# CY8C5888LTI_LP097 register map
File version: 0.1
Registers are 8-bit, read-write, no defined reset value unless marked. A register's access mark holds for its fields unless they carry their own. Offsets are from the block's base; [hi:lo] are bit positions; {n}, {i} and the like mark numbered series; 'fields as' and 'values as' point back to an identical list.

## Timer_1
Base 0x00000000
0x40006506 Timer_1_COUNTER 16-bit — UDB.A0 - Current Down Counter Value
0x40006526 Timer_1_PERIOD 16-bit — UDB.D0 - Assigned Period
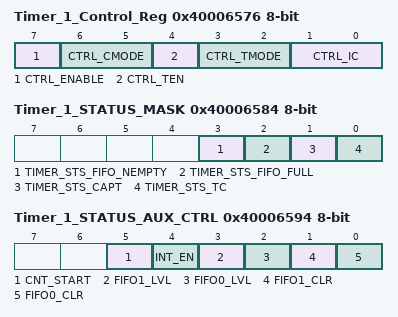
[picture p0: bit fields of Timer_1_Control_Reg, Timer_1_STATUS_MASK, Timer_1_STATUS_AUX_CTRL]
0x40006576 Timer_1_Control_Reg — UDB Control Register - Assigned Control Register Value
  [7] CTRL_ENABLE — Enable the Timer
  [6:5] CTRL_CMODE — Capture Mode
  [4] CTRL_TEN — Trigger Enable Bit
  [3:2] CTRL_TMODE — Trigger Mode
  [1:0] CTRL_IC — Interrupt Count
0x40006584 Timer_1_STATUS_MASK — UDB Status bits Interrupt Mask Enable Register
  [3] TIMER_STS_FIFO_NEMPTY ro — FIFO Empty status
  [2] TIMER_STS_FIFO_FULL ro — FIFO Full Status
  [1] TIMER_STS_CAPT ro — Enables the Interrupt on Capture
  [0] TIMER_STS_TC ro — Enables the Interrupt on TC
0x40006594 Timer_1_STATUS_AUX_CTRL — UDB Auxilliary Control Register
  [5] CNT_START — FIFO0 clear
    0=E_CNT_START0 (Disable counter); 1=E_CNT_START1 (Enable counter)
  [4] INT_EN
    0=E_INT_EN0 (Interrupt disabled); 1=E_INT_EN1 (Interrupt enabled)
  [3] FIFO1_LVL — FIFO level
    0=E_FIFO_LVL_0 (FIFO LVL: input mode: FIFO not full; output mode: FIFO not empty); 1=E_FIFO_LVL_1 (FIFO LVL: input mode: FIFO at least 1/2 empty; output mode: FIFO at least 1/2 full)
  [2] FIFO0_LVL — FIFO level
    values as FIFO1_LVL
  [1] FIFO1_CLR — FIFO1 clear
    0=E_FIFO_CLR_0 (Normal FIFO operation); 1=E_FIFO_CLR_1 (Clear FIFO state)
  [0] FIFO0_CLR — FIFO0 clear
    values as FIFO1_CLR

## PWM_5
Base 0x00000000
0x40006524 PWM_5_COMPARE_Reg 16-bit — UDB.D0 - Assigned Compare Value
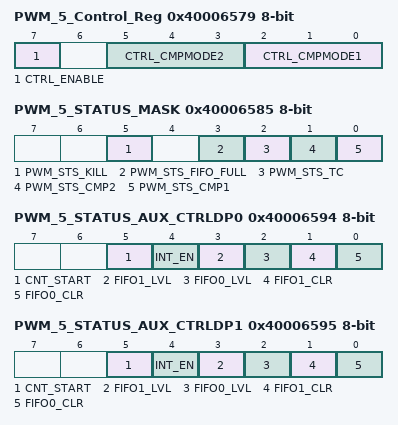
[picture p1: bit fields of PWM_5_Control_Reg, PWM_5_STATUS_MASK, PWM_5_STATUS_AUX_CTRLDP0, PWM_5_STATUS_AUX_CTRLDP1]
0x40006579 PWM_5_Control_Reg — UDB Control Register - Assigned Control Register Value
  [7] CTRL_ENABLE — Enable the PWM
  [5:3] CTRL_CMPMODE2 — Compare mode 2
  [2:0] CTRL_CMPMODE1 — Compare mode 1
0x40006585 PWM_5_STATUS_MASK — UDB Status bits Interrupt Mask Enable Register
  [5] PWM_STS_KILL ro — Enables the Interrupt on Kill
  [3] PWM_STS_FIFO_FULL ro — FIFO Full Status Mask
  [2] PWM_STS_TC ro — Enables the Interrupt on Terminal Count
  [1] PWM_STS_CMP2 ro — Enables the Interrupt on Compare 2
  [0] PWM_STS_CMP1 ro — Enables the Interrupt on Compare 1
0x40006594 PWM_5_STATUS_AUX_CTRLDP0 — UDB Auxilliary Control Register
  [5] CNT_START — FIFO0 clear
    0=E_CNT_START0 (Disable counter); 1=E_CNT_START1 (Enable counter)
  [4] INT_EN
    0=E_INT_EN0 (Interrupt disabled); 1=E_INT_EN1 (Interrupt enabled)
  [3] FIFO1_LVL — FIFO level
    0=E_FIFO_LVL_0 (FIFO LVL: input mode: FIFO not full; output mode: FIFO not empty); 1=E_FIFO_LVL_1 (FIFO LVL: input mode: FIFO at least 1/2 empty; output mode: FIFO at least 1/2 full)
  [2] FIFO0_LVL — FIFO level
    values as FIFO1_LVL
  [1] FIFO1_CLR — FIFO1 clear
    0=E_FIFO_CLR_0 (Normal FIFO operation); 1=E_FIFO_CLR_1 (Clear FIFO state)
  [0] FIFO0_CLR — FIFO0 clear
    values as FIFO1_CLR
0x40006595 PWM_5_STATUS_AUX_CTRLDP1 — UDB Auxilliary Control Register
  fields as PWM_5_STATUS_AUX_CTRLDP0

## U — UART
Base 0x00000000
0x40006444 TX_U_TX_DATA — TX Data Register
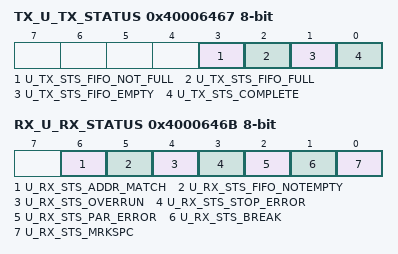
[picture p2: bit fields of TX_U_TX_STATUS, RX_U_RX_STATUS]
0x40006467 TX_U_TX_STATUS — TX status register
  [3] U_TX_STS_FIFO_NOT_FULL ro, [2] U_TX_STS_FIFO_FULL ro, [1] U_TX_STS_FIFO_EMPTY ro, [0] U_TX_STS_COMPLETE ro
0x4000646B RX_U_RX_STATUS — RX status register
  [6] U_RX_STS_ADDR_MATCH ro, [5] U_RX_STS_FIFO_NOTEMPTY ro, [4] U_RX_STS_OVERRUN ro, [3] U_RX_STS_STOP_ERROR ro, [2] U_RX_STS_PAR_ERROR ro, [1] U_RX_STS_BREAK ro, [0] U_RX_STS_MRKSPC ro
0x40006528 RX_U_RX_ADDRESS1 — RX Address1 Register
0x40006538 RX_U_RX_ADDRESS2 — RX Address2 Register
0x40006548 RX_U_RX_DATA — RX Data Register

## USB — USBFS
Base 0x00000000
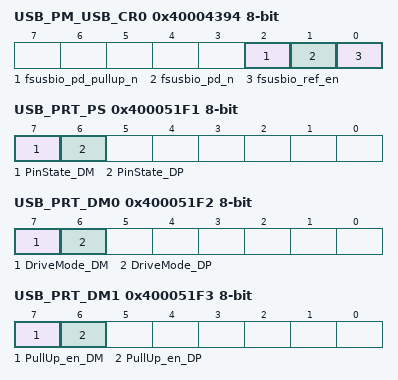
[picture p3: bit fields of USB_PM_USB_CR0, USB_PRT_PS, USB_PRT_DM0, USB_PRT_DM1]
0x40004394 USB_PM_USB_CR0 — USB Power Mode Control Register 0
  [2] fsusbio_pd_pullup_n, [1] fsusbio_pd_n, [0] fsusbio_ref_en
0x400043A5 USB_PM_ACT_CFG — Active Power Mode Configuration Register
0x400043B5 USB_PM_STBY_CFG — Standby Power Mode Configuration Register
0x400051F1 USB_PRT_PS — Port Pin State Register
  [7] PinState_DM ro, [6] PinState_DP ro
0x400051F2 USB_PRT_DM0 — Port Drive Mode Register
  [7] DriveMode_DM, [6] DriveMode_DP
0x400051F3 USB_PRT_DM1 — Port Drive Mode Register
  [7] PullUp_en_DM, [6] PullUp_en_DP
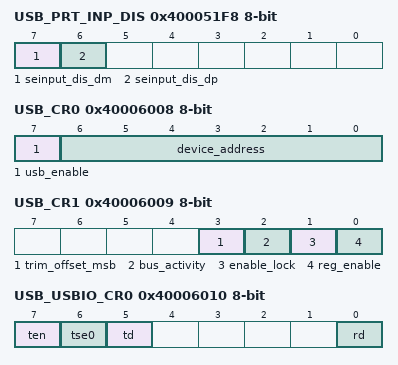
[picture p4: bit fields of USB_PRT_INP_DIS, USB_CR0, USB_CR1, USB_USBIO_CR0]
0x400051F8 USB_PRT_INP_DIS — Input buffer disable override
  [7] seinput_dis_dm, [6] seinput_dis_dp
0x40006000 USB_EP0_DR0 — bmRequestType
0x40006001 USB_EP0_DR1 — bRequest
0x40006002 USB_EP0_DR2 — wValueLo
0x40006003 USB_EP0_DR3 — wValueHi
0x40006004 USB_EP0_DR4 — wIndexLo
0x40006005 USB_EP0_DR5 — wIndexHi
0x40006006 USB_EP0_DR6 — lengthLo
0x40006007 USB_EP0_DR7 — lengthHi
0x40006008 USB_CR0 — USB Control Register 0
  [7] usb_enable, [6:0] device_address ro
0x40006009 USB_CR1 — USB Control Register 1
  [3] trim_offset_msb, [2] bus_activity, [1] enable_lock, [0] reg_enable
{0x40005FFE+0x10*i} USB_SIE_EP{i}_CR0 (i=1..8) — The Endpoint{i} Control Register
0x40006010 USB_USBIO_CR0 — USBIO Control Register 0
  [7] ten, [6] tse0, [5] td, [0] rd ro
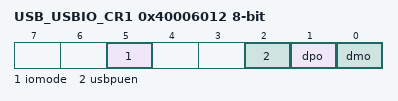
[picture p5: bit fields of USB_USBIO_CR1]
0x40006012 USB_USBIO_CR1 — USBIO Control Register 1
  [5] iomode, [2] usbpuen, [1] dpo ro, [0] dmo ro
0x4000608C USB_BUF_SIZE — Dedicated Endpoint Buffer Size Register
0x4000608E USB_EP_ACTIVE — Endpoint Active Indication Register
0x4000608F USB_EP_TYPE — Endpoint Type (IN/OUT) Indication
0x4000609D USB_USB_CLK_EN — USB Block Clock Enable Register

## PWM_1
Base 0x00000000
0x4000652A PWM_1_COMPARE_Reg 16-bit — UDB.D0 - Assigned Compare Value
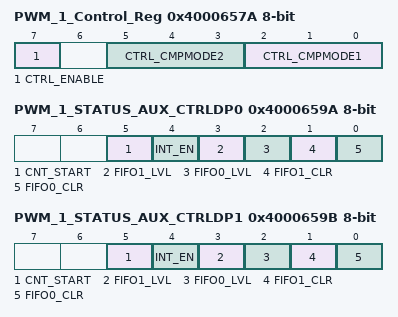
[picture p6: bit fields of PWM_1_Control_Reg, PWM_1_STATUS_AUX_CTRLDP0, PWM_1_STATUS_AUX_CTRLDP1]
0x4000657A PWM_1_Control_Reg — UDB Control Register - Assigned Control Register Value
  [7] CTRL_ENABLE — Enable the PWM
  [5:3] CTRL_CMPMODE2 — Compare mode 2
  [2:0] CTRL_CMPMODE1 — Compare mode 1
0x4000659A PWM_1_STATUS_AUX_CTRLDP0 — UDB Auxilliary Control Register
  [5] CNT_START — FIFO0 clear
    0=E_CNT_START0 (Disable counter); 1=E_CNT_START1 (Enable counter)
  [4] INT_EN
    0=E_INT_EN0 (Interrupt disabled); 1=E_INT_EN1 (Interrupt enabled)
  [3] FIFO1_LVL — FIFO level
    0=E_FIFO_LVL_0 (FIFO LVL: input mode: FIFO not full; output mode: FIFO not empty); 1=E_FIFO_LVL_1 (FIFO LVL: input mode: FIFO at least 1/2 empty; output mode: FIFO at least 1/2 full)
  [2] FIFO0_LVL — FIFO level
    values as FIFO1_LVL
  [1] FIFO1_CLR — FIFO1 clear
    0=E_FIFO_CLR_0 (Normal FIFO operation); 1=E_FIFO_CLR_1 (Clear FIFO state)
  [0] FIFO0_CLR — FIFO0 clear
    values as FIFO1_CLR
0x4000659B PWM_1_STATUS_AUX_CTRLDP1 — UDB Auxilliary Control Register
  fields as PWM_1_STATUS_AUX_CTRLDP0

## RS485CTL
Base 0x4000647E
0x00 RS485CTL_CONTROL_REG

## ADC_SAR — SAR ADC
Base 0x00000000
0x40004616 SAR_TR0 — SAR trim register
{0x40005908+i} SAR_CSR{i} (i=0..6) — SAR status and control register {i}
0x40005B28 SAR_SW0 — SAR Analog Routing Register 0
{0x40005B28+i} SAR_SW{i} (i=2..4) — SAR Analog Routing Register {i}
0x40005B2E SAR_SW6 — SAR Analog Routing Register 6
0x40005B2F SAR_CLK — SAR Clock Selection Register
0x40005BA2 SAR_WRK 16-bit — SAR working register
